# WS63 register map
File version: 1.0
CPU: other r0p0, little endian, MPU, FPU, 3 interrupt priority bits
Registers are 32-bit, read-write, reset 0x0 unless marked. A register's access mark holds for its fields unless they carry their own. Offsets are from the block's base; [hi:lo] are bit positions; {n}, {i} and the like mark numbered series.

## CMU — Clock management unit registers used by WS63 clock and PLL setup
Base 0x40003000
0x134 RF_RX_LDO — RF receiver 1.0 V LDO control used by the application-owned RF power-up sequence
  [15:0] control — Complete vendor-defined RF RX LDO control value
0x138 RF_LNA_LDO — RF low-noise amplifier 1.0 V LDO control
  [15:0] control — Complete vendor-defined RF LNA LDO control value
0x140 RF_VCO_LDO — RF voltage-controlled oscillator 1.0 V LDO control
  [15:0] control — Complete vendor-defined RF VCO LDO control value
0x144 RF_ABB_LDO — RF analog-baseband 1.0 V LDO control
  [15:0] control — Complete vendor-defined RF analog-baseband LDO control value
0x148 RF_PLL_LDO — RF phase-locked-loop 1.0 V LDO control
  [15:0] control — Complete vendor-defined RF PLL LDO control value
0x168 RF_TX_LDO — RF transmitter 1.8 V LDO control
  [15:0] control — Complete vendor-defined RF TX LDO control value
0x19C EXCEP_RO_RG ro — Exception read-only status register
  [12] fnpll_lock_grm — FNPLL lock status queried by the vendor cmu_is_fnpll_locked path
0x230 RF_ADDA_ISO — RF ADC/DAC isolation release control
  [1:0] control — RF ADC/DAC isolation control value
0x400 RF_PLL_REFERENCE — RF PLL reference-clock enable control
  [2:0] control — Complete vendor-defined RF PLL reference control value
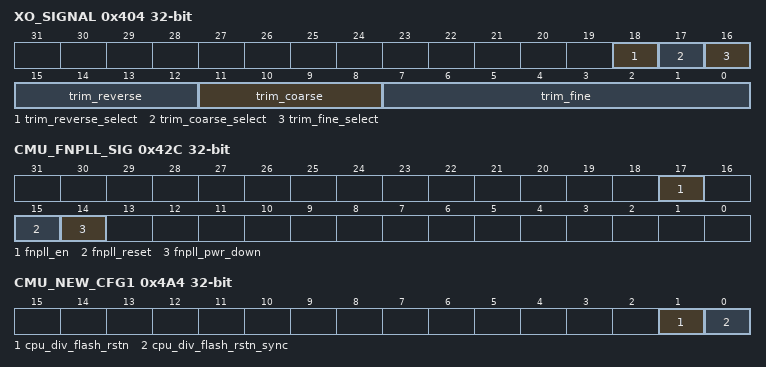
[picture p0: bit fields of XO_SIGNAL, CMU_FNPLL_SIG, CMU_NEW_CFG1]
0x404 XO_SIGNAL — Crystal-oscillator trim and signal control
  [18] trim_reverse_select — Use the programmed reverse trim code
  [17] trim_coarse_select — Use the programmed coarse trim code
  [16] trim_fine_select — Use the programmed fine trim code
  [15:12] trim_reverse — Crystal oscillator reverse trim code
  [11:8] trim_coarse — Crystal oscillator coarse trim code
  [7:0] trim_fine — Crystal oscillator fine trim code
0x42C CMU_FNPLL_SIG — FNPLL signal and control register
  [17] fnpll_en — FNPLL enable bit used by the vendor PM path
  [15] fnpll_reset — FNPLL reset/control bit used by the vendor PM path
  [14] fnpll_pwr_down — FNPLL power-down control used by the vendor PM path
0x4A0 CMU_NEW_CFG0 — CMU divider reset-sync control 0
  [0] cmu_div_ad_rstn_sync — I2S/SIO divider reset-sync release bit used by sio_porting_clock_enable
0x4A4 CMU_NEW_CFG1 — CMU flash/CPU divider reset control
  [1] cpu_div_flash_rstn — Flash divider reset release bit written before switching flash clock to PLL
  [0] cpu_div_flash_rstn_sync — Flash divider reset-sync bit written before switching flash clock to PLL

## GLB_CTL_M — Main core global control - BCPU/MCPU reset status, chip reset, AON CRG
Base 0x40002000
0x30 BCPU_RESET_STS — BCPU reset status register
  [31:0] bcpu_reset_sts ro — BCPU reset status
0x34 MCPU_RESET_STS — MCPU reset status register
  [31:0] mcpu_reset_sts ro — MCPU reset status
0x3C RESET_STS_CLEAR wo — Reset status clear register
  [31:0] rst_sts_clear — Write 0xFF to clear all reset status bits
0x100 AON_CRG_CKEN_CTL — AON CRG clock enable control
  [4] wdt_gate — WDT clock gate control at bit[4]
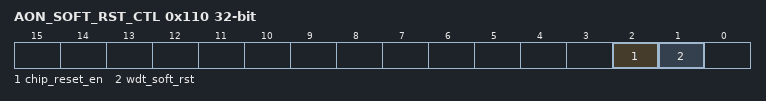
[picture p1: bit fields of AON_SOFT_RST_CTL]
0x110 AON_SOFT_RST_CTL — AON soft reset and chip reset control
  [2] chip_reset_en — Chip reset enable: 1=assert chip reset
  [1] wdt_soft_rst — WDT soft reset at bit[1]

## SPACC — Security accelerator - AES/SM4/LEA/TDES symmetric crypto, HASH/HMAC
Base 0x44100000
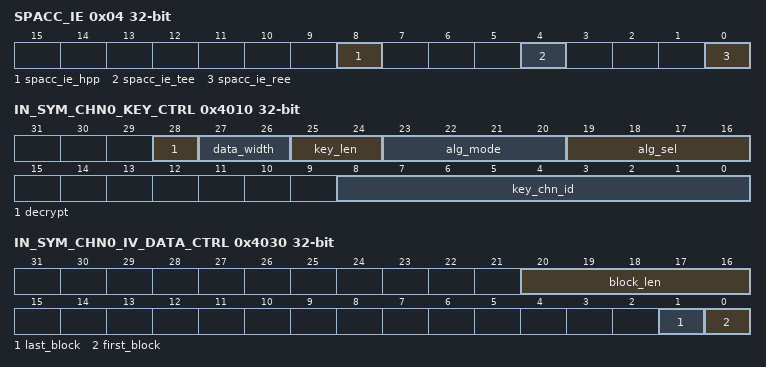
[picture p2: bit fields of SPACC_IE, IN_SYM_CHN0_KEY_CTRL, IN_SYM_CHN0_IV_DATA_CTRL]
0x04 SPACC_IE — SPACC interrupt enable
  [8] spacc_ie_hpp — HPP interrupt enable
  [4] spacc_ie_tee — TEE interrupt enable
  [0] spacc_ie_ree — REE interrupt enable
0x08 SPACC_INT_RAW_SYM_CLR_FINISH — Sym clear finish raw interrupt
  [15:0] raw_sym_clr_finish_int ro — Raw interrupt for sym clear finish
0x20 SPACC_SYM_CHN_LOCK — Sym channel lock register
  [31:0] sym_chn_lock — Symmetric channel lock status
0x40 SPACC_HASH_CHN_LOCK — Hash channel lock register
  [31:0] hash_chn_lock — Hash channel lock status
0x60 SPACC_SYM_CHN_CLEAR_REQ — Sym channel clear request
  [31:0] sym_chn_clear_req wo — Clear request for symmetric channels
0x68 SPACC_HASH_CHN_CLEAR_REQ — Hash channel clear request
  [31:0] hash_chn_clear_req wo — Clear request for hash channels
0x200 SPACC_BUS_ERR — Bus error register
  [31:0] bus_err ro — Bus error status
0x4000 IN_SYM_CHN0_CTRL — Sym channel 0 control register (no-DMA mode)
  [31] sym_chn0_req wo — Channel 0 start request
0x4004 IN_SYM_CHN0_SPECIAL_CTRL — Sym channel 0 special control
  [0] sym_chn0_odd_even — Odd/even control for TDES
0x4010 IN_SYM_CHN0_KEY_CTRL — Sym channel 0 key control (no-DMA mode)
  [28] decrypt — Decrypt: 0=encrypt; 1=decrypt
  [27:26] data_width — Data width: 0=128bit; 1=64bit; 2=32bit
    0=Width128 (128-bit data path); 1=Width64 (64-bit data path); 2=Width32 (32-bit data path)
  [25:24] key_len — Key length: 0=128bit; 1=192bit; 2=256bit
    0=Key128 (128-bit key); 1=Key192 (192-bit key); 2=Key256 (256-bit key)
  [23:20] alg_mode — Mode: 1=ECB; 3=CBC; 6=CTR; 0xA=GCM; 0xC=CMAC
    1=ECB (Electronic Codebook); 3=CBC (Cipher Block Chaining); 6=CTR (Counter mode); 7=OFB (Output Feedback); 8=CFB (Cipher Feedback); 9=CCM (CCM authenticated encryption); 10=GCM (Galois/Counter Mode); 11=GCTR (GCM CTR only); 12=CMAC (Cipher-based MAC)
  [19:16] alg_sel — Algorithm: 2=AES; 4=LEA; 5=SM4; 6=GHASH; 7=TDES
    2=AES (AES algorithm); 4=LEA (LEA (Lightweight Encryption Algorithm)); 5=SM4 (SM4 (Chinese national standard)); 6=GHASH (GHASH (GCM authentication)); 7=TDES (Triple DES)
  [8:0] key_chn_id — Key channel ID
0x4030 IN_SYM_CHN0_IV_DATA_CTRL — Sym channel 0 IV/data control (register mode)
  [20:16] block_len — Block length (in bytes)
  [1] last_block — Last block flag
  [0] first_block — First block flag
0x4040 IN_SYM_CHN0_IV0 — Sym channel 0 IV word 0 (register mode)
  [31:0] iv0 — IV[31:0]
{0x4040+4i} IN_SYM_CHN0_IV{i} (i=1..3) — Sym channel 0 IV word {i}
  [31:0] iv{i} — IV[{32i+31}:{32i}]
0x4050 IN_SYM_CHN0_DATA0 — Sym channel 0 data word 0 (register mode)
  [31:0] data0 — Input data[31:0]
0x8610 SYM_CHANN_RAW_INT — Sym channel raw interrupt status
  [15:0] sym_chann_raw_int ro — Raw interrupt per channel [15:0]
